VERSION ""

NS_ :

BS_:

BU_: XXX

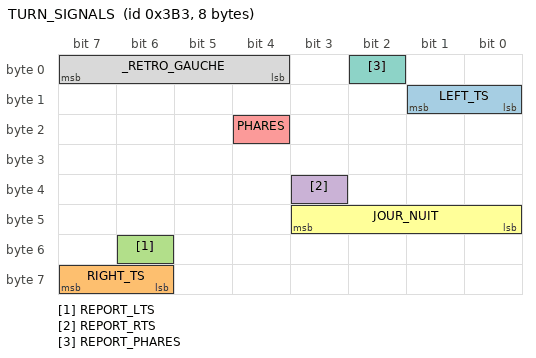
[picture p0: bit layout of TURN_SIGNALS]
BO_ 947 TURN_SIGNALS: 8 XXX
 SG_ LEFT_TS : 9|2@0+ (1,0) [0|1] "" XXX
 SG_ RIGHT_TS : 63|2@0+ (1,0) [0|1] "" XXX
 SG_ REPORT_LTS : 54|1@0+ (1,0) [0|1] "" XXX
 SG_ REPORT_RTS : 35|1@0+ (1,0) [0|1] "" XXX
 SG_ PHARES : 20|1@0+ (1,0) [0|1] "" XXX
 SG_ JOUR_NUIT : 43|4@0+ (1,0) [0|1] "" XXX
 SG_ REPORT_PHARES : 2|1@0+ (1,0) [0|1] "" XXX
 SG_ _RETRO_GAUCHE : 7|4@0+ (1,0) [0|1] "" XXX
